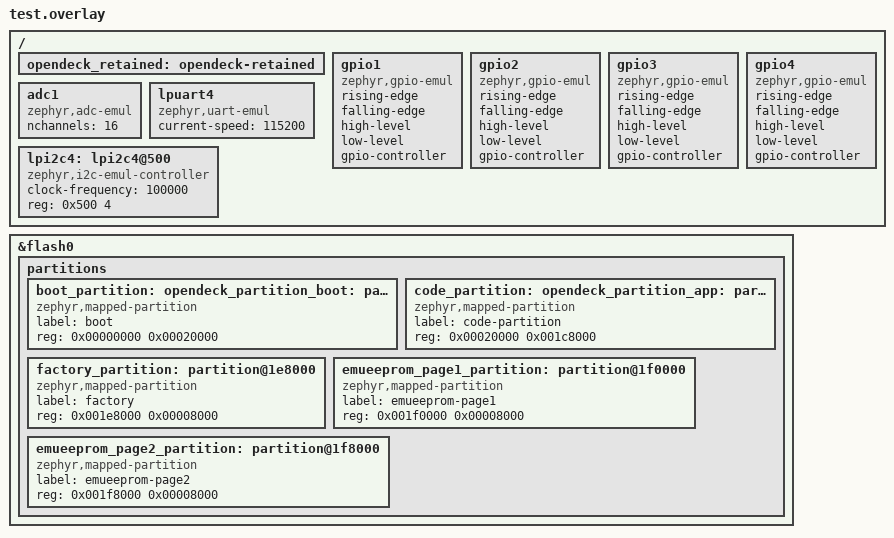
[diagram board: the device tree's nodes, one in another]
/ {
    opendeck_retained: opendeck-retained {
    };

    gpio1: gpio1 {
        compatible = "zephyr,gpio-emul";
        rising-edge;
        falling-edge;
        high-level;
        low-level;
        gpio-controller;
        #gpio-cells = <2>;
        status = "okay";
    };

    gpio2: gpio2 {
        compatible = "zephyr,gpio-emul";
        rising-edge;
        falling-edge;
        high-level;
        low-level;
        gpio-controller;
        #gpio-cells = <2>;
        status = "okay";
    };

    gpio3: gpio3 {
        compatible = "zephyr,gpio-emul";
        rising-edge;
        falling-edge;
        high-level;
        low-level;
        gpio-controller;
        #gpio-cells = <2>;
        status = "okay";
    };

    gpio4: gpio4 {
        compatible = "zephyr,gpio-emul";
        rising-edge;
        falling-edge;
        high-level;
        low-level;
        gpio-controller;
        #gpio-cells = <2>;
        status = "okay";
    };

    adc1: adc1 {
        compatible = "zephyr,adc-emul";
        nchannels = <16>;
        #io-channel-cells = <1>;
        status = "okay";
    };

    lpuart4: lpuart4 {
        compatible = "zephyr,uart-emul";
        current-speed = <115200>;
        status = "okay";
    };

    lpi2c4: lpi2c4@500 {
        compatible = "zephyr,i2c-emul-controller";
        #address-cells = <1>;
        #size-cells = <0>;
        #forward-cells = <1>;
        clock-frequency = <100000>;
        reg = <0x500 4>;
        status = "okay";
    };
};

&flash0 {
    partitions {
        boot_partition: partition@0 {
            compatible = "zephyr,mapped-partition";
            label = "boot";
            reg = <0x00000000 0x00020000>;
        };

        code_partition: partition@20000 {
            compatible = "zephyr,mapped-partition";
            label = "code-partition";
            reg = <0x00020000 0x001c8000>;
        };

        factory_partition: partition@1e8000 {
            compatible = "zephyr,mapped-partition";
            label = "factory";
            reg = <0x001e8000 0x00008000>;
        };

        emueeprom_page1_partition: partition@1f0000 {
            compatible = "zephyr,mapped-partition";
            label = "emueeprom-page1";
            reg = <0x001f0000 0x00008000>;
        };

        emueeprom_page2_partition: partition@1f8000 {
            compatible = "zephyr,mapped-partition";
            label = "emueeprom-page2";
            reg = <0x001f8000 0x00008000>;
        };
    };
};

opendeck_partition_boot: &boot_partition {};

opendeck_partition_app: &code_partition {};
